# nrf9151 register map
Vendor: Nordic Semiconductor; Series: nrf91; File version: 1
CPU: CM33 r0p4, little endian, MPU, FPU, 3 interrupt priority bits, 69 interrupts
Registers are 32-bit, read-write, reset 0x0 unless marked. A register's access mark holds for its fields unless they carry their own. Offsets are from the block's base; [hi:lo] are bit positions; lines under a group give offsets from that group; {n}, {i} and the like mark numbered series.

## FICR_S — Factory Information Configuration Registers
Base 0x00FF0000
0x140 SIPINFO group — SIP-specific device info
  0x00 PARTNO ro reset 0xFFFFFFFF — SIP part number
    [31:0] PARTNO
      0x9151=Device is an nRF9151 sip
  {0x4+j} HWREVISION[{j}] (j=0..3) 8-bit ro reset 0xFF — Description collection: SIP hardware revision, encoded in ASCII, ex B0A or B1A
    [7:0] HWREVISION
  {0x8+j} VARIANT[{j}] (j=0..3) 8-bit ro reset 0xFF — Description collection: SIP VARIANT, encoded in ASCII, ex SIAA, SIBA or SICA
    [7:0] VARIANT
0x200 INFO group — Device info
  {0x4+4j} DEVICEID[{j}] (j=0..1) ro reset 0xFFFFFFFF — Description collection: Device identifier
    [31:0] DEVICEID — 64 bit unique device identifier
  0x0C PART ro reset 0xFFFFFFFF — Part code
    [31:0] PART
      0x9151=N9151 (nRF9151); 0x9120=N9120 (nRF9120)
  0x10 VARIANT ro reset 0xFFFFFFF — Part Variant, Hardware version and Production configuration
    [31:0] VARIANT — Part Variant, Hardware version and Production configuration, encoded as ASCII
      0x41414141=AAAA; 0x41414130=AAA0; 0x41414230=AAB0; 0x41414330=AAC0
  0x14 PACKAGE ro reset 0x2000 — Package option
    [31:0] PACKAGE
      0x2002=CF (CFxx - 236 ball wlCSP)
  0x18 RAM ro reset 0x100 — RAM variant
    [31:0] RAM
      0x100=K256 (256 kByte RAM); 0xFFFFFFFF=Unspecified
  0x1C FLASH ro reset 0x400 — Flash variant
    [31:0] FLASH
      0x400=K1024 (1 MByte FLASH)
  0x20 CODEPAGESIZE ro reset 0x1000 — Code memory page size
    [31:0] CODEPAGESIZE
      0x1000=K4096 (4 kByte)
  0x24 CODESIZE ro reset 0x100 — Code memory size
    [31:0] CODESIZE — Code memory size in number of pages Total code space is: CODEPAGESIZE * CODESIZE
      0x100=P256 (256 pages)
  0x28 DEVICETYPE ro reset 0xFFFFFFFF
    [31:0] DEVICETYPE
      0=Die (Device is an physical DIE); 0xFFFFFFFF=FPGA (Device is an FPGA)
{0x300+8i} TRIMCNF[{i}] (i=0..255) group — Unspecified
  0x00 ADDR ro reset 0xFFFFFFFF — Description cluster: Address
    [31:0] Address
  0x04 DATA ro reset 0xFFFFFFFF — Description cluster: Data
0xC00 TRNG90B group — NIST800-90B RNG calibration data
  0x00 BYTES ro reset 0xFFFFFFFF — Amount of bytes for the required entropy bits
  0x04 RCCUTOFF ro reset 0xFFFFFFFF — Repetition counter cutoff
  0x08 APCUTOFF ro reset 0xFFFFFFFF — Adaptive proportion cutoff
  0x0C STARTUP ro reset 0xFFFFFFFF — Amount of bytes for the startup tests
  {0xC+4j} ROSC{j} ro reset 0xFFFFFFFF (j=1..4) — Sample count for ring oscillator {j}

## UICR_S — User information configuration registers User information configuration registers
Base 0x00FF8000
0x00 APPROTECT — Access port protection
  [31:0] PALL — Blocks debugger read/write access to all CPU registers and memory mapped addresses
    0xFFFFFFFF=Unprotected; 0=Protected
0x14 XOSC32M reset 0xFFFFFFCF — Oscillator control
  [5:0] CTRL — Pierce current DAC control signals
0x1C HFXOSRC reset 0xFFFFFFFF — HFXO clock source selection
  [0] HFXOSRC
    1=XTAL (32 MHz crystal oscillator); 0=TCXO (32 MHz temperature compensated crystal oscillator (TCXO))
0x20 HFXOCNT reset 0xFFFFFFFF — HFXO startup counter
  [7:0] HFXOCNT — HFXO startup counter. Total debounce time = HFXOCNT*64 us + 0.5 us
    0=Min debounce time = (0*64 us + 0.5 us); 255=Max debounce time = (255*64 us + 0.5 us)
0x24 APPNVMCPOFGUARD reset 0xFFFFFFFF — Enable blocking NVM WRITE and aborting NVM ERASE for Application NVM in POFWARN condition .
  [0] NVMCPOFGUARDEN — Enable blocking NVM WRITE and aborting NVM ERASE in POFWARN condition
    0=Disabled (NVM WRITE and NVM ERASE are not blocked in POFWARN condition); 1=Enabled (NVM WRITE and NVM ERASE are blocked in POFWARN condition)
0x2C SECUREAPPROTECT — Secure access port protection
  [31:0] PALL — Blocks debugger read/write access to all secure CPU registers and secure memory mapped addresses
    0xFFFFFFFF=Unprotected; 0=Protected
0x30 ERASEPROTECT — Erase protection
  [31:0] PALL — Blocks NVMC ERASEALL and CTRLAP ERASEALL functionality
    0xFFFFFFFF=Unprotected; 0=Protected
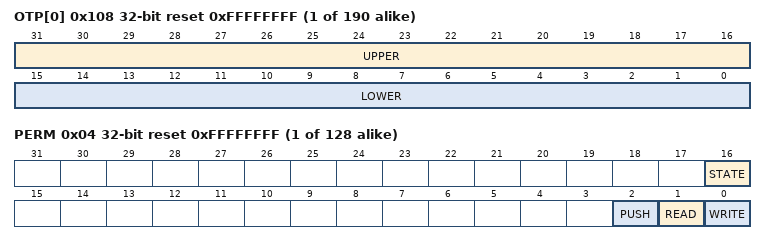
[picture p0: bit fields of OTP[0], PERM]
{0x108+4i} OTP[{i}] (i=0..189) reset 0xFFFFFFFF — Description collection: One time programmable memory
  [31:16] UPPER rw-once — Upper half word
  [15:0] LOWER rw-once — Lower half word
0x400 KEYSLOT group — Unspecified
  {0x0+8j} CONFIG[{j}] (j=0..127) group — Unspecified
    0x00 DEST reset 0xFFFFFFFF — Description cluster: Destination address where content of the key value registers (KEYSLOT.KEYn.VALUE[0-3]) will be pushed by KMU. Note that this address must match that of a peripherals APB mapped write-only key registers, else the KMU can push this key value into an address range which the CPU can potentially read.
      [31:0] DEST — Secure APB destination address
    0x04 PERM reset 0xFFFFFFFF — Description cluster: Define permissions for the key slot. Bits 0-15 and 16-31 can only be written when equal to 0xFFFF.
      [16] STATE — Revocation state for the key slot
        0=Revoked (Key value registers can no longer be read or pushed); 1=Active (Key value registers are readable (if enabled) and can be pushed (if enabled))
      [2] PUSH — Push permission for key slot
        0=Disabled (Disable pushing of key value registers over secure APB, but can be read if field READ is Enabled); 1=Enabled (Enable pushing of key value registers over secure APB. Register KEYSLOT.CONFIGn.DEST must contain a valid destination address!)
      [1] READ — Read permission for key slot
        0=Disabled (Disable read from key value registers); 1=Enabled (Enable read from key value registers)
      [0] WRITE — Write permission for key slot
        0=Disabled (Disable write to the key value registers); 1=Enabled (Enable write to the key value registers)
  {0x400+0x10*j} KEY[{j}] (j=0..127) group — Unspecified
    {0x0+4k} VALUE[{k}] (k=0..3) reset 0xFFFFFFFF — Description collection: Define bits [31+o*32:0+o*32] of value assigned to KMU key slot.
      [31:0] VALUE — Define bits [31+o*32:0+o*32] of value assigned to KMU key slot

## Notices in the file
Copyright (c) 2010 - 2024, Nordic Semiconductor ASA All rights reserved.
SPDX-License-Identifier: BSD-3-Clause
Redistribution and use in source and binary forms, with or without
modification, are permitted provided that the following conditions are met:
1. Redistributions of source code must retain the above copyright notice, this
list of conditions and the following disclaimer.
2. Redistributions in binary form must reproduce the above copyright
notice, this list of conditions and the following disclaimer in the
documentation and/or other materials provided with the distribution.
3. Neither the name of Nordic Semiconductor ASA nor the names of its
contributors may be used to endorse or promote products derived from this
software without specific prior written permission.
THIS SOFTWARE IS PROVIDED BY THE COPYRIGHT HOLDERS AND CONTRIBUTORS "AS IS"
AND ANY EXPRESS OR IMPLIED WARRANTIES, INCLUDING, BUT NOT LIMITED TO, THE
IMPLIED WARRANTIES OF MERCHANTABILITY, AND FITNESS FOR A PARTICULAR PURPOSE
ARE DISCLAIMED. IN NO EVENT SHALL NORDIC SEMICONDUCTOR ASA OR CONTRIBUTORS BE
LIABLE FOR ANY DIRECT, INDIRECT, INCIDENTAL, SPECIAL, EXEMPLARY, OR
CONSEQUENTIAL DAMAGES (INCLUDING, BUT NOT LIMITED TO, PROCUREMENT OF
SUBSTITUTE GOODS OR SERVICES; LOSS OF USE, DATA, OR PROFITS; OR BUSINESS
INTERRUPTION) HOWEVER CAUSED AND ON ANY THEORY OF LIABILITY, WHETHER IN
CONTRACT, STRICT LIABILITY, OR TORT (INCLUDING NEGLIGENCE OR OTHERWISE)
ARISING IN ANY WAY OUT OF THE USE OF THIS SOFTWARE, EVEN IF ADVISED OF THE
POSSIBILITY OF SUCH DAMAGE.
